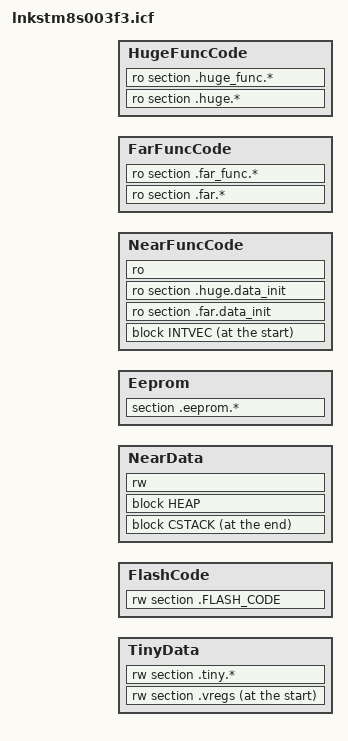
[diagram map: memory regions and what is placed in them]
/////////////////////////////////////////////////////////////////
//      Example ILINK command file for
//      STM8 IAR C/C++ Compiler and Assembler.
//
//      Copyright 2013 IAR Systems AB.
//
/////////////////////////////////////////////////////////////////

define memory with size = 16M;

//define region TinyData = [from 0x00 to 0xFF];
define region TinyData = [from 0x00 to 0x9F];

define region FlashCode = [from 0xA0 to 0x17F];

//define region NearData = [from 0x0000 to 0x03FF];
define region NearData = [from 0x0180 to 0x03FF];


define region Eeprom = [from 0x4000 to 0x407F];

define region NearFuncCode = [from 0x8000 to 0x9FFF];

define region FarFuncCode = [from 0x8000 to 0x9FFF];

define region HugeFuncCode = [from 0x8000 to 0x9FFF];


/////////////////////////////////////////////////////////////////

define block CSTACK with size = _CSTACK_SIZE  {};

define block HEAP  with size = _HEAP_SIZE {};

define block INTVEC with size = 0x80 { ro section .intvec };

// Initialization
initialize by copy { rw,
	       						 ro section .tiny.rodata,
                     section FLASH_CODE};

do not initialize { section .vregs };
do not initialize { section .*.noinit };


// Placement
place at start of TinyData      { rw section .vregs };
place in TinyData               { rw section .tiny.* };

//place at start of FlashCode      { rw section .FLASH_CODE };
place in FlashCode               { rw section .FLASH_CODE };


place at end of NearData        { block CSTACK };
place in NearData               { block HEAP,
                                  rw };     // includes rw section .near.*

place at start of NearFuncCode  { block INTVEC };
place in NearFuncCode           { ro section .far.data_init,
                                  ro section .huge.data_init,
                                  ro };     // includes ro section .near_func.*
                                                                    
                                                                    
place in FarFuncCode            { ro section .far.*,
                                  ro section .far_func.* };

place in HugeFuncCode           { ro section .huge.*,
                                  ro section .huge_func.* };

place in Eeprom                 { section .eeprom.* };
/////////////////////////////////////////////////////////////////
